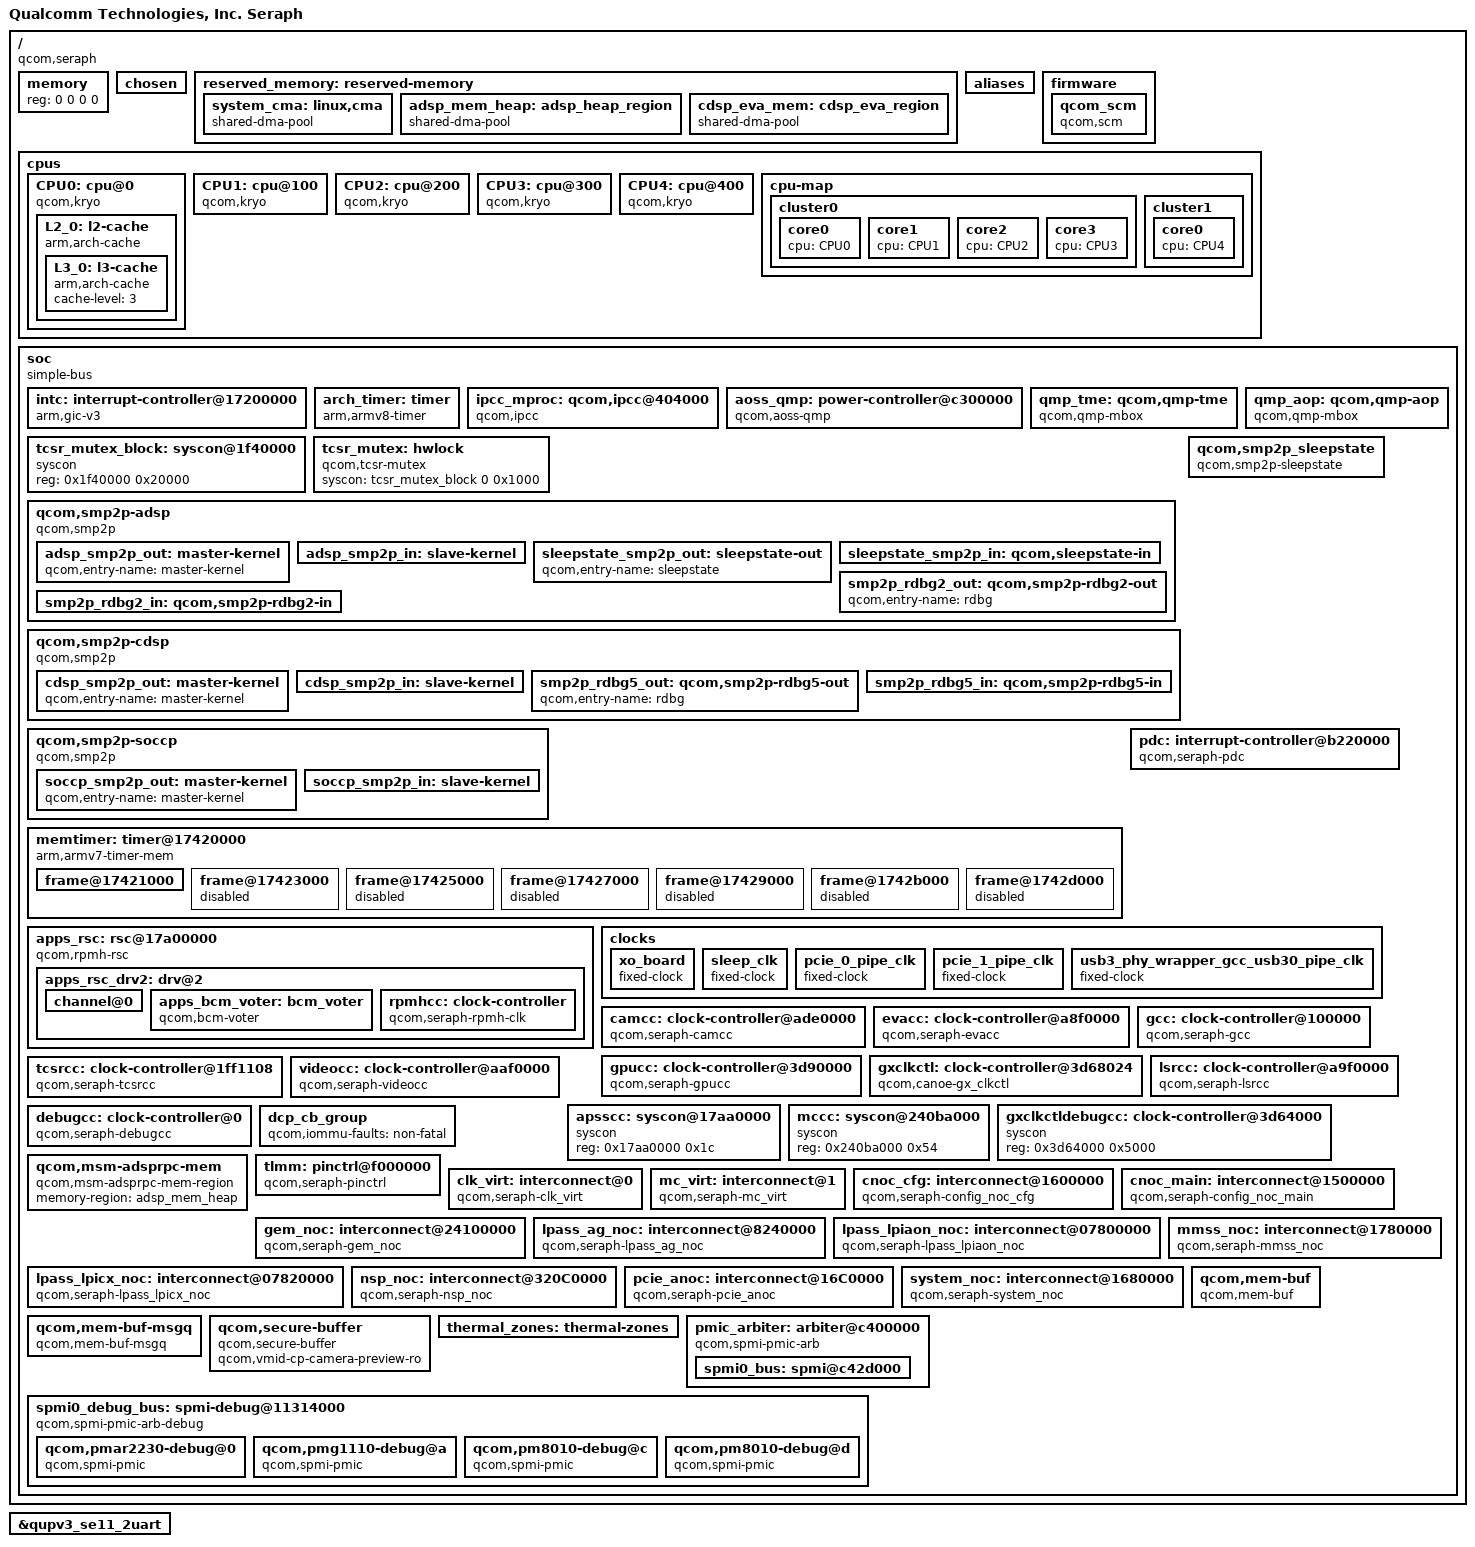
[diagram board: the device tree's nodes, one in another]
// SPDX-License-Identifier: BSD-3-Clause
/*
 * Copyright (c) Qualcomm Technologies, Inc. and/or its subsidiaries.
 */

#include <dt-bindings/interrupt-controller/arm-gic.h>
#include <dt-bindings/soc/qcom,rpmh-rsc.h>
#include <dt-bindings/clock/qcom,rpmh.h>
#include <dt-bindings/clock/qcom,camcc-seraph.h>
#include <dt-bindings/clock/qcom,evacc-seraph.h>
#include <dt-bindings/clock/qcom,gcc-seraph.h>
#include <dt-bindings/clock/qcom,gpucc-seraph.h>
#include <dt-bindings/clock/qcom,lsrcc-seraph.h>
#include <dt-bindings/clock/qcom,tcsrcc-seraph.h>
#include <dt-bindings/clock/qcom,videocc-seraph.h>
#include <dt-bindings/interconnect/qcom,seraph.h>
#include <dt-bindings/soc/qcom,ipcc.h>
#include <dt-bindings/spmi/spmi.h>
#include <dt-bindings/regulator/qcom,rpmh-regulator-levels.h>

/ {
	model = "Qualcomm Technologies, Inc. Seraph";
	compatible = "qcom,seraph";
	qcom,msm-id = <672 0x10000>;
	interrupt-parent = <&intc>;

	#address-cells = <2>;
	#size-cells = <2>;
	memory { device_type = "memory"; reg = <0 0 0 0>; };

	chosen: chosen {
		bootargs = "loglevel=8 earlycon earlycon=qcom_geni,0x00A94000 qcom_geni_serial.con_enabled=1 log_buf_len=256K  console=ttyMSM0,115200,n8 bootconfig swiotlb=0 kasan=off cgroup_disable=pressure cgroup.memory=nokmem,nosocket disable_dma32=on restrict_cma_redirect=false";
	};

	reserved_memory: reserved-memory {};

	aliases {
		serial0 = &qupv3_se11_2uart;
		hsuart0 = &qupv3_se7_4uart;
		hsuart1 = &qupv3_se3_2uart;
		hsuart2 = &qupv3_se1_1uart;
		i2c0 = &qupv3_se0_i2c;
		i2c1 = &qupv3_se1_i2c;
		i2c2 = &qupv3_se2_i2c;
		i2c3 = &qupv3_se3_i2c;
		i2c4 = &qupv3_se4_i2c;
		i2c5 = &qupv3_se5_i2c;
		i2c6 = &qupv3_se6_i2c;
		i2c8 = &qupv3_se8_i2c;
		i2c9 = &qupv3_se9_i2c;
		i2c10 = &qupv3_se10_i2c;
		spi0 = &qupv3_se0_spi;
		spi1 = &qupv3_se1_spi;
		spi2 = &qupv3_se2_spi;
		spi3 = &qupv3_se3_spi;
		spi4 = &qupv3_se4_spi;
		spi5 = &qupv3_se5_spi;
		spi6 = &qupv3_se6_spi;
		spi8 = &qupv3_se8_spi;
		spi9 = &qupv3_se9_spi;
		spi10 = &qupv3_se10_spi;
	 };

	firmware: firmware {
		qcom_scm: qcom_scm { };
	};

	cpus {
		#address-cells = <2>;
		#size-cells = <0>;

		CPU0: cpu@0 {
			device_type = "cpu";
			compatible = "qcom,kryo";
			reg = <0x0 0x0>;
			enable-method = "psci";
			cpu-release-addr = <0x0 0x90000000>;
			next-level-cache = <&L2_0>;
			L2_0: l2-cache {
				compatible = "arm,arch-cache";
				cache-level = <2>;
				next-level-cache = <&L3_0>;

				L3_0: l3-cache {
					compatible = "arm,arch-cache";
					cache-level = <3>;
				};
			};
		};

		CPU1: cpu@100 {
			device_type = "cpu";
			compatible = "qcom,kryo";
			reg = <0x0 0x100>;
			enable-method = "psci";
			cpu-release-addr = <0x0 0x90000000>;
			next-level-cache = <&L2_0>;
		};

		CPU2: cpu@200 {
			device_type = "cpu";
			compatible = "qcom,kryo";
			reg = <0x0 0x200>;
			enable-method = "psci";
			cpu-release-addr = <0x0 0x90000000>;
			next-level-cache = <&L2_0>;
		};

		CPU3: cpu@300 {
			device_type = "cpu";
			compatible = "qcom,kryo";
			reg = <0x0 0x300>;
			enable-method = "psci";
			cpu-release-addr = <0x0 0x90000000>;
			next-level-cache = <&L2_0>;
		};

		CPU4: cpu@400 {
			device_type = "cpu";
			compatible = "qcom,kryo";
			reg = <0x0 0x400>;
			enable-method = "psci";
			cpu-release-addr = <0x0 0x90000000>;
			next-level-cache = <&L2_0>;
		};

		cpu-map {
			cluster0 {
				core0 {
					cpu = <&CPU0>;
				};

				core1 {
					cpu = <&CPU1>;
				};

				core2 {
					cpu = <&CPU2>;
				};

				core3 {
					cpu = <&CPU3>;
				};
			};

			cluster1 {
				core0 {
					cpu = <&CPU4>;
				};
			};
		};
	};

	soc: soc { };

};

&soc {
	#address-cells = <1>;
	#size-cells = <1>;

	ranges = <0 0 0 0xffffffff>;
	compatible = "simple-bus";

	intc: interrupt-controller@17200000 {
		compatible = "arm,gic-v3";
		#interrupt-cells = <3>;
		interrupt-controller;
		#redistributor-regions = <1>;
		redistributor-stride = <0x0 0x20000>;
		reg = <0x17200000 0x10000>,       /* GICD */
		     <0x17260000 0xA0000>;       /* GICR * 5 */
		interrupts = <GIC_PPI 9 IRQ_TYPE_LEVEL_HIGH>;
	};

	arch_timer: timer {
		compatible = "arm,armv8-timer";
		interrupts = <GIC_PPI 13 (GIC_CPU_MASK_SIMPLE(8) | IRQ_TYPE_LEVEL_LOW)>,
			     <GIC_PPI 14 (GIC_CPU_MASK_SIMPLE(8) | IRQ_TYPE_LEVEL_LOW)>,
			     <GIC_PPI 11 (GIC_CPU_MASK_SIMPLE(8) | IRQ_TYPE_LEVEL_LOW)>,
			     <GIC_PPI 12 (GIC_CPU_MASK_SIMPLE(8) | IRQ_TYPE_LEVEL_LOW)>;
		clock-frequency = <19200000>;
	};

	ipcc_mproc: qcom,ipcc@404000 {
		compatible = "qcom,ipcc";
		reg = <0x404000 0x1000>;
		interrupts = <GIC_SPI 229 IRQ_TYPE_LEVEL_HIGH>;
		interrupt-controller;
		#interrupt-cells = <3>;
		#mbox-cells = <2>;
	};

	aoss_qmp: power-controller@c300000 {
		compatible = "qcom,aoss-qmp";
		reg = <0xc300000 0x400>;
		interrupt-parent = <&ipcc_mproc>;
		interrupts = <IPCC_CLIENT_AOP
			      IPCC_MPROC_SIGNAL_GLINK_QMP
			      IRQ_TYPE_EDGE_RISING>;
		mboxes = <&ipcc_mproc IPCC_CLIENT_AOP
			  IPCC_MPROC_SIGNAL_GLINK_QMP>;

		#power-domain-cells = <1>;
		#clock-cells = <0>;
	};

	qmp_tme: qcom,qmp-tme {
		compatible = "qcom,qmp-mbox";
		qcom,remote-pid = <14>;
		mboxes = <&ipcc_mproc IPCC_CLIENT_TME
			  IPCC_MPROC_SIGNAL_GLINK_QMP>;
		mbox-names = "tme_qmp";
		interrupt-parent = <&ipcc_mproc>;
		interrupts = <IPCC_CLIENT_TME
			      IPCC_MPROC_SIGNAL_GLINK_QMP
			      IRQ_TYPE_EDGE_RISING>;

		label = "tme";
		qcom,early-boot;
		priority = <0>;
		mbox-desc-offset = <0x0>;
		#mbox-cells = <1>;
	};

	qmp_aop: qcom,qmp-aop {
		compatible = "qcom,qmp-mbox";
		qcom,qmp = <&aoss_qmp>;
		label = "aop";
		#mbox-cells = <1>;
	};

	tcsr_mutex_block: syscon@1f40000 {
		compatible = "syscon";
		reg = <0x1f40000 0x20000>;
	};

	tcsr_mutex: hwlock {
		compatible = "qcom,tcsr-mutex";
		syscon = <&tcsr_mutex_block 0 0x1000>;
		#hwlock-cells = <1>;
	};

	qcom,smp2p-adsp {
		compatible = "qcom,smp2p";
		qcom,smem = <443>, <429>;
		interrupt-parent = <&ipcc_mproc>;
		interrupts = <IPCC_CLIENT_LPASS IPCC_MPROC_SIGNAL_SMP2P
			      IRQ_TYPE_EDGE_RISING>;
		mboxes = <&ipcc_mproc IPCC_CLIENT_LPASS
			  IPCC_MPROC_SIGNAL_SMP2P>;
		qcom,local-pid = <0>;
		qcom,remote-pid = <2>;

		adsp_smp2p_out: master-kernel {
			qcom,entry-name = "master-kernel";
			#qcom,smem-state-cells = <1>;
		};

		adsp_smp2p_in: slave-kernel {
			qcom,entry-name = "slave-kernel";
			interrupt-controller;
			#interrupt-cells = <2>;
		};

		sleepstate_smp2p_out: sleepstate-out {
			qcom,entry-name = "sleepstate";
			#qcom,smem-state-cells = <1>;
		};

		sleepstate_smp2p_in: qcom,sleepstate-in {
			qcom,entry-name = "sleepstate_see";
			interrupt-controller;
			#interrupt-cells = <2>;
		};

		smp2p_rdbg2_out: qcom,smp2p-rdbg2-out {
			qcom,entry-name = "rdbg";
			#qcom,smem-state-cells = <1>;
		};

		smp2p_rdbg2_in: qcom,smp2p-rdbg2-in {
			qcom,entry-name = "rdbg";
			interrupt-controller;
			#interrupt-cells = <2>;
		};
	};

	qcom,smp2p-cdsp {
		compatible = "qcom,smp2p";
		qcom,smem = <94>, <432>;
		interrupt-parent = <&ipcc_mproc>;
		interrupts = <IPCC_CLIENT_CDSP IPCC_MPROC_SIGNAL_SMP2P
			      IRQ_TYPE_EDGE_RISING>;
		mboxes = <&ipcc_mproc IPCC_CLIENT_CDSP IPCC_MPROC_SIGNAL_SMP2P>;
		qcom,local-pid = <0>;
		qcom,remote-pid = <5>;

		cdsp_smp2p_out: master-kernel {
			qcom,entry-name = "master-kernel";
			#qcom,smem-state-cells = <1>;
		};

		cdsp_smp2p_in: slave-kernel {
			qcom,entry-name = "slave-kernel";
			interrupt-controller;
			#interrupt-cells = <2>;
		};

		smp2p_rdbg5_out: qcom,smp2p-rdbg5-out {
			qcom,entry-name = "rdbg";
			#qcom,smem-state-cells = <1>;
		};

		smp2p_rdbg5_in: qcom,smp2p-rdbg5-in {
			qcom,entry-name = "rdbg";
			interrupt-controller;
			#interrupt-cells = <2>;
		};
	};

	qcom,smp2p-soccp {
		compatible = "qcom,smp2p";
		qcom,smem = <617>, <616>;
		interrupt-parent = <&ipcc_mproc>;
		interrupts = <IPCC_CLIENT_SOCCP IPCC_MPROC_SIGNAL_SMP2P
			      IRQ_TYPE_EDGE_RISING>;
		mboxes = <&ipcc_mproc IPCC_CLIENT_SOCCP IPCC_MPROC_SIGNAL_SMP2P>;
		qcom,local-pid = <0>;
		qcom,remote-pid = <19>;

		soccp_smp2p_out: master-kernel {
			qcom,entry-name = "master-kernel";
			#qcom,smem-state-cells = <1>;
		};

		soccp_smp2p_in: slave-kernel {
			qcom,entry-name = "slave-kernel";
			interrupt-controller;
			#interrupt-cells = <2>;
		};
	};

	qcom,smp2p_sleepstate {
		compatible = "qcom,smp2p-sleepstate";
		qcom,smem-states = <&sleepstate_smp2p_out 0>;
		interrupt-parent = <&sleepstate_smp2p_in>;
		interrupts = <0 0>;
		interrupt-names = "smp2p-sleepstate-in";
	};

	memtimer: timer@17420000 {
		#address-cells = <1>;
		#size-cells = <1>;
		ranges;
		compatible = "arm,armv7-timer-mem";
		reg = <0x17420000 0x1000>;
		clock-frequency = <19200000>;

		frame@17421000 {
			frame-number = <0>;
			interrupts = <GIC_SPI 8 IRQ_TYPE_LEVEL_HIGH>,
				     <GIC_SPI 6 IRQ_TYPE_LEVEL_HIGH>;
			reg = <0x17421000 0x1000>,
			      <0x17422000 0x1000>;
		};

		frame@17423000 {
			frame-number = <1>;
			interrupts = <GIC_SPI 9 IRQ_TYPE_LEVEL_HIGH>;
			reg = <0x17423000 0x1000>;
			status = "disabled";
		};

		frame@17425000 {
			frame-number = <2>;
			interrupts = <GIC_SPI 10 IRQ_TYPE_LEVEL_HIGH>;
			reg = <0x17425000 0x1000>;
			status = "disabled";
		};

		frame@17427000 {
			frame-number = <3>;
			interrupts = <GIC_SPI 11 IRQ_TYPE_LEVEL_HIGH>;
			reg = <0x17427000 0x1000>;
			status = "disabled";
		};

		frame@17429000 {
			frame-number = <4>;
			interrupts = <GIC_SPI 12 IRQ_TYPE_LEVEL_HIGH>;
			reg = <0x17429000 0x1000>;
			status = "disabled";
		};

		frame@1742b000 {
			frame-number = <5>;
			interrupts = <GIC_SPI 13 IRQ_TYPE_LEVEL_HIGH>;
			reg = <0x1742b000 0x1000>;
			status = "disabled";
		};

		frame@1742d000 {
			frame-number = <6>;
			interrupts = <GIC_SPI 14 IRQ_TYPE_LEVEL_HIGH>;
			reg = <0x1742d000 0x1000>;
			status = "disabled";
		};
	};

	apps_rsc: rsc@17a00000 {
		label = "apps_rsc";
		compatible = "qcom,rpmh-rsc";
		reg = <0x17a00000 0x10000>,
		      <0x17a10000 0x10000>,
		      <0x17a20000 0x10000>;
		reg-names = "drv-0", "drv-1", "drv-2";
		qcom,drv-count = <3>;
		interrupts = <GIC_SPI 3 IRQ_TYPE_LEVEL_HIGH>,
			     <GIC_SPI 4 IRQ_TYPE_LEVEL_HIGH>,
			     <GIC_SPI 5 IRQ_TYPE_LEVEL_HIGH>;

		apps_rsc_drv2: drv@2 {
			qcom,drv-id = <2>;
			qcom,tcs-offset = <0xd00>;
			qcom,tcs-distance = <0x2a0>;
			channel@0 {
				qcom,tcs-config = <ACTIVE_TCS    3>,
						  <SLEEP_TCS     2>,
						  <WAKE_TCS      2>,
						  <CONTROL_TCS   0>,
						  <FAST_PATH_TCS 1>;
			};

			apps_bcm_voter: bcm_voter {
				compatible = "qcom,bcm-voter";
			};

			rpmhcc: clock-controller {
				compatible = "qcom,seraph-rpmh-clk";
				#clock-cells = <1>;
			};
		};
	};

	pdc: interrupt-controller@b220000 {
		compatible = "qcom,seraph-pdc", "qcom,pdc";
		reg = <0xb220000 0x10000>, <0x174000f0 0x64>;
		qcom,pdc-ranges = <0 221 1>, <1 227 2>, <3 238 4>,
				  <8 263 2>, <10 293 3>, <14 297 2>,
				  <16 348 2>, <18 351 3>, <22 355 2>,
				  <24 641 1>, <25 358 1>, <26 376 2>,
				  <28 443 1>, <30 242 1>, <31 296 1>,
				  <32 354 1>, <33 357 1>, <34 444 3>,
				  <37 472 1>, <40 447 1>, <41 461 1>,
				  <42 473 1>, <43 462 1>, <44 584 1>,
				  <45 586 1>, <47 607 2>, <49 642 1>,
				  <50 656 1>, <51 527 1>, <61 505 1>,
				  <62 605 1>, <63 372 2>, <65 378 1>,
				  <66 431 1>, <70 528 46>, <116 609 31>,
				  <147 63 1>, <148 716 12>, <160 251 5>,
				  <165 379 1>;
		#interrupt-cells = <2>;
		interrupt-parent = <&intc>;
		interrupt-controller;
	};

	clocks {
		xo_board: xo_board {
			compatible = "fixed-clock";
			clock-frequency = <38400000>;
			clock-output-names = "xo_board";
			#clock-cells = <0>;
		};

		sleep_clk: sleep_clk {
			compatible = "fixed-clock";
			clock-frequency = <32000>;
			clock-output-names = "sleep_clk";
			#clock-cells = <0>;
		};

		pcie_0_pipe_clk: pcie_0_pipe_clk {
			compatible = "fixed-clock";
			clock-frequency = <1000>;
			clock-output-names = "pcie_0_pipe_clk";
			#clock-cells = <0>;
		};

		pcie_1_pipe_clk: pcie_1_pipe_clk {
			compatible = "fixed-clock";
			clock-frequency = <1000>;
			clock-output-names = "pcie_1_pipe_clk";
			#clock-cells = <0>;
		};

		usb3_phy_wrapper_gcc_usb30_pipe_clk: usb3_phy_wrapper_gcc_usb30_pipe_clk {
			compatible = "fixed-clock";
			clock-frequency = <1000>;
			clock-output-names = "usb3_phy_wrapper_gcc_usb30_pipe_clk";
			#clock-cells = <0>;
		};
	};

	camcc: clock-controller@ade0000 {
		compatible = "qcom,seraph-camcc", "syscon";
		reg = <0xade0000 0x20000>;
		reg-name = "cc_base";
		vdd_cx-supply = <&VDD_CX_LEVEL>;
		vdd_mx-supply = <&VDD_MX_LEVEL>;
		clocks = <&rpmhcc RPMH_CXO_CLK>,
			 <&sleep_clk>, <&gcc GCC_CAMERA_AHB_CLK>;
		clock-names = "bi_tcxo",
			      "sleep_clk", "iface";
		#clock-cells = <1>;
		#reset-cells = <1>;
		#power-domain-cells = <1>;
	};

	evacc: clock-controller@a8f0000 {
		compatible = "qcom,seraph-evacc", "syscon";
		reg = <0xa8f0000 0x10000>;
		reg-name = "cc_base";
		vdd_mm-supply = <&VDD_MM_LEVEL>;
		vdd_mx-supply = <&VDD_MX_LEVEL>;
		clocks = <&rpmhcc RPMH_CXO_CLK>,
			 <&sleep_clk>, <&gcc GCC_EVA_AHB_CLK>;
		clock-names = "bi_tcxo",
			      "sleep_clk", "iface";
		#clock-cells = <1>;
		#reset-cells = <1>;
		#power-domain-cells = <1>;
	};

	gcc: clock-controller@100000 {
		compatible = "qcom,seraph-gcc", "syscon";
		reg = <0x100000 0x1f4200>;
		reg-name = "cc_base";
		vdd_cx-supply = <&VDD_CX_LEVEL>;
		vdd_mx-supply = <&VDD_MX_LEVEL>;
		clocks = <&rpmhcc RPMH_CXO_CLK>,
			 <&pcie_0_pipe_clk>,
			 <&pcie_1_pipe_clk>,
			 <&sleep_clk>,
			 <&usb3_phy_wrapper_gcc_usb30_pipe_clk>;
		clock-names = "bi_tcxo",
			      "pcie_0_pipe_clk",
			      "pcie_1_pipe_clk",
			      "sleep_clk",
			      "usb3_phy_wrapper_gcc_usb30_pipe_clk";
		#clock-cells = <1>;
		#reset-cells = <1>;
		#power-domain-cells = <1>;
	};

	gpucc: clock-controller@3d90000 {
		compatible = "qcom,seraph-gpucc", "syscon";
		reg = <0x3d90000 0x9800>;
		reg-name = "cc_base";
		vdd_cx-supply = <&VDD_CX_LEVEL>;
		vdd_mx-supply = <&VDD_MX_LEVEL>;
		clocks = <&rpmhcc RPMH_CXO_CLK>,
			 <&gcc GCC_GPU_GPLL0_CLK_SRC>,
			 <&gcc GCC_GPU_GPLL0_DIV_CLK_SRC>;
		clock-names = "bi_tcxo",
			      "gpll0_out_main",
			      "gpll0_out_main_div";
		#clock-cells = <1>;
		#reset-cells = <1>;
		#power-domain-cells = <1>;
	};

	gxclkctl: clock-controller@3d68024 {
		compatible = "qcom,canoe-gx_clkctl";
		reg = <0x3d68024 0x8>;
		reg-name = "cc_base";
		power-domains = <&gpucc GPU_CC_CX_GDSC>;
		vdd_gfx-supply = <&VDD_GFX_LEVEL>;
		#power-domain-cells = <1>;
	};

	lsrcc: clock-controller@a9f0000 {
		compatible = "qcom,seraph-lsrcc", "syscon";
		reg = <0xa9f0000 0x10000>;
		reg-name = "cc_base";
		vdd_mm-supply = <&VDD_MM_LEVEL>;
		vdd_mx-supply = <&VDD_MX_LEVEL>;
		clocks = <&rpmhcc RPMH_CXO_CLK>,
			 <&sleep_clk>, <&gcc GCC_LSR_AHB_CLK>;
		clock-names = "bi_tcxo",
			      "sleep_clk", "iface";
		#clock-cells = <1>;
		#reset-cells = <1>;
		#power-domain-cells = <1>;
	};

	tcsrcc: clock-controller@1ff1108 {
		compatible = "qcom,seraph-tcsrcc", "syscon";
		reg = <0x1ff1108 0x18>;
		reg-name = "cc_base";
		#clock-cells = <1>;
		#reset-cells = <1>;
	};

	videocc: clock-controller@aaf0000 {
		compatible = "qcom,seraph-videocc", "syscon";
		reg = <0xaaf0000 0x10000>;
		reg-name = "cc_base";
		vdd_mm-supply = <&VDD_MM_LEVEL>;
		vdd_mx-supply = <&VDD_MX_LEVEL>;
		clocks = <&rpmhcc RPMH_CXO_CLK>, <&gcc GCC_VIDEO_AHB_CLK>;
		clock-names = "bi_tcxo", "iface";
		#clock-cells = <1>;
		#reset-cells = <1>;
		#power-domain-cells = <1>;
	};

	apsscc: syscon@17aa0000 {
		compatible = "syscon";
		reg = <0x17aa0000 0x1c>;
	};

	mccc: syscon@240ba000 {
		compatible = "syscon";
		reg = <0x240ba000 0x54>;
	};

	gxclkctldebugcc: clock-controller@3d64000 {
		compatible = "syscon";
		reg = <0x3d64000 0x5000>;
	};

	debugcc: clock-controller@0 {
		compatible = "qcom,seraph-debugcc";
		qcom,apsscc = <&apsscc>;
		qcom,camcc = <&camcc>;
		qcom,evacc = <&evacc>;
		qcom,gcc = <&gcc>;
		qcom,gpucc = <&gpucc>;
		qcom,gxclkctl = <&gxclkctldebugcc>;
		qcom,lsrcc = <&lsrcc>;
		qcom,videocc = <&videocc>;
		qcom,mccc = <&mccc>;
		clocks = <&rpmhcc RPMH_CXO_CLK>, <&camcc 0>,
			 <&evacc 0>, <&gcc 0>, <&gpucc 0>,
			 <&lsrcc 0>, <&videocc 0>;
		clock-names = "xo_clk_src", "camcc",
			      "evacc", "gcc", "gpucc",
			      "lsrcc", "videocc";
		#clock-cells = <1>;
	};

	dcp_cb_group: dcp_cb_group {
		qcom,iommu-faults = "non-fatal";
	};

	qcom,msm-adsprpc-mem {
		compatible = "qcom,msm-adsprpc-mem-region";
		memory-region = <&adsp_mem_heap>;
	};

	tlmm: pinctrl@f000000 {
		compatible = "qcom,seraph-pinctrl";
		reg = <0xF000000 0x1000000>;
		interrupts = <GIC_SPI 208 IRQ_TYPE_LEVEL_HIGH>;
		gpio-controller;
		#gpio-cells = <2>;
		interrupt-controller;
		#interrupt-cells = <2>;
		wakeup-parent = <&pdc>;
		qcom,gpios-reserved = <18 19>;
	};

	clk_virt: interconnect@0 {
		compatible = "qcom,seraph-clk_virt";
		#interconnect-cells = <1>;
		qcom,bcm-voter-names = "hlos";
		qcom,bcm-voters = <&apps_bcm_voter>;
	};

	mc_virt: interconnect@1 {
		compatible = "qcom,seraph-mc_virt";
		#interconnect-cells = <1>;
		qcom,bcm-voter-names = "hlos";
		qcom,bcm-voters = <&apps_bcm_voter>;
	};

	cnoc_cfg: interconnect@1600000 {
		compatible = "qcom,seraph-config_noc_cfg";
		reg = <0x01600000 0x7200>;
		#interconnect-cells = <1>;
		qcom,bcm-voter-names = "hlos";
		qcom,bcm-voters = <&apps_bcm_voter>;
	};

	cnoc_main: interconnect@1500000 {
		compatible = "qcom,seraph-config_noc_main";
		reg = <0x01500000 0x1a200>;
		#interconnect-cells = <1>;
		qcom,bcm-voter-names = "hlos";
		qcom,bcm-voters = <&apps_bcm_voter>;
	};

	gem_noc: interconnect@24100000 {
		compatible = "qcom,seraph-gem_noc";
		reg = <0x24100000 0x163080>;
		#interconnect-cells = <1>;
		qcom,bcm-voter-names = "hlos";
		qcom,bcm-voters = <&apps_bcm_voter>;
	};

	lpass_ag_noc: interconnect@8240000 {
		compatible = "qcom,seraph-lpass_ag_noc";
		reg = <0x08240000 0xe080>;
		#interconnect-cells = <1>;
		qcom,bcm-voter-names = "hlos";
		qcom,bcm-voters = <&apps_bcm_voter>;
	};

	lpass_lpiaon_noc: interconnect@07800000 {
		compatible = "qcom,seraph-lpass_lpiaon_noc";
		reg = <0x07800000 0x19080>;
		#interconnect-cells = <1>;
		qcom,bcm-voter-names = "hlos";
		qcom,bcm-voters = <&apps_bcm_voter>;
	};

	lpass_lpicx_noc: interconnect@07820000 {
		compatible = "qcom,seraph-lpass_lpicx_noc";
		reg = <0x07820000 0x44080>;
		#interconnect-cells = <1>;
		qcom,bcm-voter-names = "hlos";
		qcom,bcm-voters = <&apps_bcm_voter>;
	};

	mmss_noc: interconnect@1780000 {
		compatible = "qcom,seraph-mmss_noc";
		reg = <0x01780000 0x6b800>;
		#interconnect-cells = <1>;
		qcom,bcm-voter-names = "hlos";
		qcom,bcm-voters = <&apps_bcm_voter>;
	};

	nsp_noc: interconnect@320C0000 {
		compatible = "qcom,seraph-nsp_noc";
		reg = <0x320C0000 0x1f400>;
		#interconnect-cells = <1>;
		qcom,bcm-voter-names = "hlos";
		qcom,bcm-voters = <&apps_bcm_voter>;
	};

	pcie_anoc: interconnect@16C0000 {
		compatible = "qcom,seraph-pcie_anoc";
		reg = <0x016C0000 0xe400>;
		#interconnect-cells = <1>;
		qcom,bcm-voter-names = "hlos";
		qcom,bcm-voters = <&apps_bcm_voter>;
		clocks = <&gcc GCC_AGGRE_NOC_PCIE_AXI_CLK>,
			 <&gcc GCC_CFG_NOC_PCIE_ANOC_AHB_CLK>;
	};

	system_noc: interconnect@1680000 {
		compatible = "qcom,seraph-system_noc";
		reg = <0x01680000 0x2d800>;
		#interconnect-cells = <1>;
		qcom,bcm-voter-names = "hlos";
		qcom,bcm-voters = <&apps_bcm_voter>;
		clocks = <&gcc GCC_AGGRE_USB3_PRIM_AXI_CLK>,
			 <&gcc GCC_SDCC1_AHB_CLK>,
			 <&gcc GCC_SDCC2_AHB_CLK>,
			 <&rpmhcc RPMH_IPA_CLK>;
	};

	qcom,mem-buf {
		compatible = "qcom,mem-buf";
		qcom,mem-buf-capabilities = "supplier";
		qcom,vmid = <3>;
	};

	qcom,mem-buf-msgq {
		compatible = "qcom,mem-buf-msgq";
	};

	qcom,secure-buffer {
		compatible = "qcom,secure-buffer";
		qcom,vmid-cp-camera-preview-ro;
	};

	thermal_zones: thermal-zones {};

	pmic_arbiter: arbiter@c400000 {
		compatible = "qcom,spmi-pmic-arb";
		reg = <0xc400000 0x3000>,
		      <0xc500000 0x400000>,
		      <0xc440000 0x80000>;
		reg-names = "core", "chnls", "obsrvr";

		qcom,ee = <0>;
		qcom,channel = <0>;

		#address-cells = <1>;
		#size-cells = <1>;
		ranges;

		spmi0_bus: spmi@c42d000 {
			reg = <0xc42d000 0x4000>,
			      <0xc4c0000 0x10000>;
			reg-names = "cnfg", "intr";

			interrupt-names = "periph_irq";
			interrupts-extended = <&pdc 1 IRQ_TYPE_LEVEL_HIGH>;
			interrupt-controller;
			#interrupt-cells = <4>;

			#address-cells = <2>;
			#size-cells = <0>;
		};
	};

	spmi0_debug_bus: spmi-debug@11314000 {
		compatible = "qcom,spmi-pmic-arb-debug";
		reg = <0x11314000 0x60>, <0x221c8784 0x4>;
		reg-names = "core", "fuse";
		clocks = <&aoss_qmp>;
		clock-names = "core_clk";
		qcom,fuse-enable-bit = <18>;
		#address-cells = <2>;
		#size-cells = <0>;
		depends-on-supply = <&spmi0_bus>;

		qcom,pmar2230-debug@0 {
			compatible = "qcom,spmi-pmic";
			reg = <0 SPMI_USID>;
			#address-cells = <2>;
			#size-cells = <0>;
			qcom,can-sleep;
		};

		qcom,pmg1110-debug@a {
			compatible = "qcom,spmi-pmic";
			reg = <10 SPMI_USID>;
			#address-cells = <2>;
			#size-cells = <0>;
			qcom,can-sleep;
		};

		qcom,pm8010-debug@c {
			compatible = "qcom,spmi-pmic";
			reg = <12 SPMI_USID>;
			#address-cells = <2>;
			#size-cells = <0>;
			qcom,can-sleep;
		};

		qcom,pm8010-debug@d {
			compatible = "qcom,spmi-pmic";
			reg = <13 SPMI_USID>;
			#address-cells = <2>;
			#size-cells = <0>;
			qcom,can-sleep;
		};
	};

};

&firmware {
	qcom_scm {
		compatible = "qcom,scm";
	};
};

&reserved_memory {
	#address-cells = <2>;
	#size-cells = <2>;
	ranges;

	/* global autoconfigured region for contiguous allocations */
	system_cma: linux,cma {
		compatible = "shared-dma-pool";
		alloc-ranges = <0x0 0x00000000 0x0 0xffffffff>;
		reusable;
		alignment = <0x0 0x400000>;
		size = <0x0 0x2000000>;
		linux,cma-default;
	};

	adsp_mem_heap: adsp_heap_region {
		compatible = "shared-dma-pool";
		alloc-ranges = <0x0 0x00000000 0x0 0xffffffff>;
		reusable;
		alignment = <0x0 0x400000>;
		size = <0x0 0xC00000>;
	};

	/* cdsp eva shared memory */
	cdsp_eva_mem: cdsp_eva_region {
		compatible = "shared-dma-pool";
		alloc-ranges = <0x0 0x00000000 0x0 0xffffffff>;
		reusable;
		alignment = <0x0 0x400000>;
		size = <0x0 0x400000>;
	};
};

#include "seraph-reserved-memory.dtsi"
#include "msm-arm-smmu-seraph.dtsi"
#include "seraph-dma-heaps.dtsi"
#include "seraph-regulators.dtsi"
#include "seraph-pinctrl.dtsi"
#include "seraph-qupv3.dtsi"

&qupv3_se11_2uart {
	status = "ok";
};
